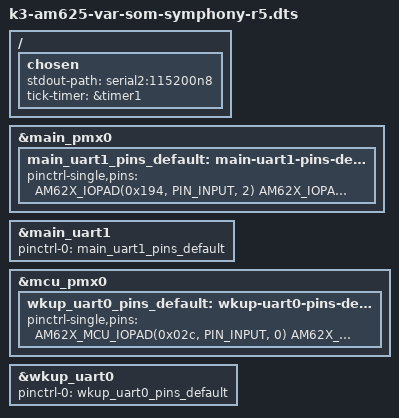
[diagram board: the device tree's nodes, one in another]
// SPDX-License-Identifier: GPL-2.0
/*
 * VAR-SOM-AM62 dts file for R5 SPL
 * Copyright (C) 2021-2022 Texas Instruments Incorporated - https://www.ti.com/
 * Copyright (C) 2023-2024 Variscite Ltd. - https://www.variscite.com/
 */

#include "k3-am625-var-som-symphony.dts"
#include "k3-am625-var-som-ddr4-1600MTs.dtsi"
#include "k3-am62-ddr.dtsi"

#include "k3-am625-var-som-symphony-u-boot.dtsi"
#include "k3-am625-var-som-r5.dtsi"

/ {
	chosen {
		stdout-path = "serial2:115200n8";
		tick-timer = &timer1;
	};
};

&main_pmx0 {
	bootph-pre-ram;
	main_uart1_pins_default: main-uart1-pins-default {
		pinctrl-single,pins = <
			AM62X_IOPAD(0x194, PIN_INPUT, 2) /* (B19) MCASP0_AXR3.UART1_CTSn */
			AM62X_IOPAD(0x198, PIN_OUTPUT, 2) /* (A19) MCASP0_AXR2.UART1_RTSn */
			AM62X_IOPAD(0x1ac, PIN_INPUT, 2) /* (E19) MCASP0_AFSR.UART1_RXD */
			AM62X_IOPAD(0x1b0, PIN_OUTPUT, 2) /* (A20) MCASP0_ACLKR.UART1_TXD */
		>;
		bootph-pre-ram;
	};
};

/* Main UART1 is used for TIFS firmware logs */
&main_uart1 {
	pinctrl-names = "default";
	pinctrl-0 = <&main_uart1_pins_default>;
	status = "okay";
	bootph-pre-ram;
};

&mcu_pmx0 {
	bootph-pre-ram;
	wkup_uart0_pins_default: wkup-uart0-pins-default {
		pinctrl-single,pins = <
			AM62X_MCU_IOPAD(0x02c, PIN_INPUT, 0) /* (C6) WKUP_UART0_CTSn */
			AM62X_MCU_IOPAD(0x030, PIN_OUTPUT, 0) /* (A4) WKUP_UART0_RTSn */
			AM62X_MCU_IOPAD(0x024, PIN_INPUT, 0) /* (B4) WKUP_UART0_RXD */
			AM62X_MCU_IOPAD(0x028, PIN_OUTPUT, 0) /* (C5) WKUP_UART0_TXD */
		>;
		bootph-pre-ram;
	};
};

/* WKUP UART0 is used for DM firmware logs */
&wkup_uart0 {
	pinctrl-names = "default";
	pinctrl-0 = <&wkup_uart0_pins_default>;
	status = "okay";
	bootph-pre-ram;
};
